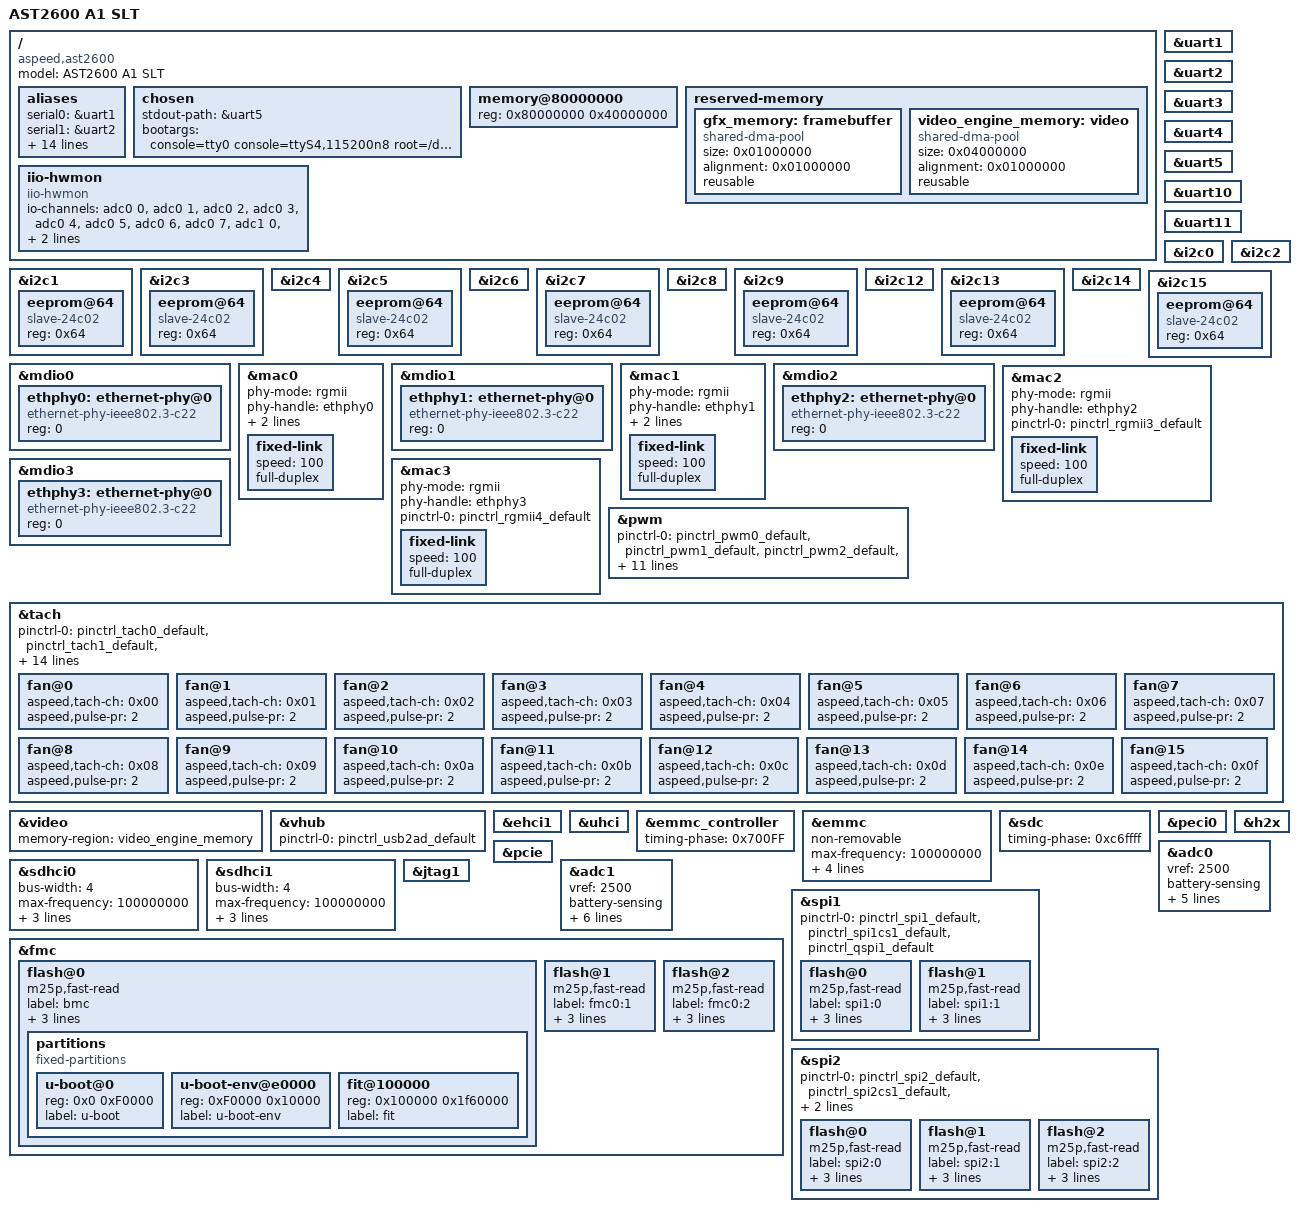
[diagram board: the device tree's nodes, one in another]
// SPDX-License-Identifier: GPL-2.0+
/dts-v1/;

#include "aspeed-g6.dtsi"

/ {
	model = "AST2600 A1 SLT";
	compatible = "aspeed,ast2600";

	aliases {
		serial0 = &uart1;
		serial1 = &uart2;
		serial2 = &uart3;
		serial3 = &uart4;
		serial4 = &uart5;
		serial5 = &uart6;
		serial6 = &uart7;
		serial7 = &uart8;
		serial8 = &uart9;
		serial9 = &uart10;
		serial10 = &uart11;
		serial11 = &uart12;
		serial12 = &uart13;
		mmc0 = &emmc;
		mmc1 = &sdhci0;
		mmc2 = &sdhci1;
	};

	chosen {
		stdout-path = &uart5;
		bootargs = "console=tty0 console=ttyS4,115200n8 root=/dev/ram rw init=/linuxrc";
	};

	memory@80000000 {
		device_type = "memory";
		reg = <0x80000000 0x40000000>;
	};

	reserved-memory {
		#address-cells = <1>;
		#size-cells = <1>;
		ranges;

		gfx_memory: framebuffer {
			size = <0x01000000>;
			alignment = <0x01000000>;
			compatible = "shared-dma-pool";
			reusable;
		};

		video_engine_memory: video {
			size = <0x04000000>;
			alignment = <0x01000000>;
			compatible = "shared-dma-pool";
			reusable;
		};
	};

	iio-hwmon {
		compatible = "iio-hwmon";
		io-channels = <&adc0 0>, <&adc0 1>, <&adc0 2>, <&adc0 3>,
				<&adc0 4>, <&adc0 5>, <&adc0 6>, <&adc0 7>,
				<&adc1 0>, <&adc1 1>, <&adc1 2>, <&adc1 3>,
				<&adc1 4>, <&adc1 5>, <&adc1 6>, <&adc1 7>;
	};	
};

&uart1 {
	status = "okay";
};

&uart2 {
	status = "okay";
};

&uart3 {
	status = "okay";
};

&uart4 {
	status = "okay";
};

&uart5 {
	status = "okay";
};

&uart10 {
	status = "okay";
};

&uart11 {
	status = "okay";
};

#if 0
&i3c0 {
	status = "okay";
};

&i3c1 {
	status = "okay";
};

&i3c2 {
        status = "okay";

        pinctrl-names = "default";
        pinctrl-0 = <&pinctrl_hvi3c3_default>;
};

&i3c3 {
        status = "okay";

        pinctrl-names = "default";
        pinctrl-0 = <&pinctrl_hvi3c4_default>;
};

&i3c4 {
	status = "okay";
};

&i3c5 {
	status = "okay";
};
#endif

&i2c0 {
	status = "okay";
};

&i2c1 {
	status = "okay";

	eeprom@64 {
		compatible = "slave-24c02";
		reg = <0x64>;
	};
};

&i2c2 {
	status = "okay";
};

&i2c3 {
	status = "okay";

	eeprom@64 {
		compatible = "slave-24c02";
		reg = <0x64>;
	};
};

&i2c4 {
	status = "okay";
};

&i2c5 {
	status = "okay";

	eeprom@64 {
		compatible = "slave-24c02";
		reg = <0x64>;
	};
};

&i2c6 {
	status = "okay";
};

&i2c7 {
	status = "okay";

	eeprom@64 {
		compatible = "slave-24c02";
		reg = <0x64>;
	};
};

&i2c8 {
	status = "okay";
};

&i2c9 {
	status = "okay";

	eeprom@64 {
		compatible = "slave-24c02";
		reg = <0x64>;
	};
};

&i2c12 {
	status = "okay";
};

&i2c13 {
	status = "okay";

	eeprom@64 {
		compatible = "slave-24c02";
		reg = <0x64>;
	};
};

&i2c14 {
	status = "okay";
};

&i2c15 {
	status = "okay";

	eeprom@64 {
		compatible = "slave-24c02";
		reg = <0x64>;
	};
};

&mdio0 {
	status = "okay";

	ethphy0: ethernet-phy@0 {
		compatible = "ethernet-phy-ieee802.3-c22";
		reg = <0>;
	};
};

&mac0 {
	status = "okay";

	phy-mode = "rgmii";
	phy-handle = <&ethphy0>;

	pinctrl-names = "default";
	pinctrl-0 = <&pinctrl_rgmii1_default>;
	no-hw-sg;

	fixed-link {
		speed = <100>;
		full-duplex;
	};
};

&mdio1 {
	status = "okay";

	ethphy1: ethernet-phy@0 {
		compatible = "ethernet-phy-ieee802.3-c22";
		reg = <0>;
	};
};

&mac1 {
	status = "okay";

	phy-mode = "rgmii";
	phy-handle = <&ethphy1>;

	pinctrl-names = "default";
	pinctrl-0 = <&pinctrl_rgmii2_default>;
	no-hw-sg;

	fixed-link {
		speed = <100>;
		full-duplex;
	};
};

&mdio2 {
	status = "okay";

	ethphy2: ethernet-phy@0 {
		compatible = "ethernet-phy-ieee802.3-c22";
		reg = <0>;
	};
};

&mac2 {
	status = "okay";

	phy-mode = "rgmii";
	phy-handle = <&ethphy2>;

	pinctrl-names = "default";
	pinctrl-0 = <&pinctrl_rgmii3_default>;

	fixed-link {
		speed = <100>;
		full-duplex;
	};
};

&mdio3 {
	status = "okay";

	ethphy3: ethernet-phy@0 {
		compatible = "ethernet-phy-ieee802.3-c22";
		reg = <0>;
	};
};

&mac3 {
	status = "okay";

	phy-mode = "rgmii";
	phy-handle = <&ethphy3>;

	pinctrl-names = "default";
	pinctrl-0 = <&pinctrl_rgmii4_default>;

	fixed-link {
		speed = <100>;
		full-duplex;
	};
};

&pwm {
	status = "okay";
	pinctrl-names = "default";
	pinctrl-0 = <&pinctrl_pwm0_default
			&pinctrl_pwm1_default
			&pinctrl_pwm2_default
			&pinctrl_pwm3_default
			&pinctrl_pwm4_default
			&pinctrl_pwm5_default
			&pinctrl_pwm6_default
			&pinctrl_pwm7_default
			&pinctrl_pwm8g1_default
			&pinctrl_pwm9g1_default
			&pinctrl_pwm10g1_default
			&pinctrl_pwm11g1_default
			&pinctrl_pwm12g1_default
			&pinctrl_pwm13g1_default
			&pinctrl_pwm14g1_default
			&pinctrl_pwm15g1_default>;
};

&tach {
	status = "okay";
	pinctrl-names = "default";
	pinctrl-0 = <&pinctrl_tach0_default
			&pinctrl_tach1_default
			&pinctrl_tach2_default
			&pinctrl_tach3_default
			&pinctrl_tach4_default
			&pinctrl_tach5_default
			&pinctrl_tach6_default
			&pinctrl_tach7_default
			&pinctrl_tach8_default
			&pinctrl_tach9_default
			&pinctrl_tach10_default
			&pinctrl_tach11_default
			&pinctrl_tach12_default
			&pinctrl_tach13_default
			&pinctrl_tach14_default
			&pinctrl_tach15_default>;
	fan@0 {
		aspeed,tach-ch = <0x00>;
		aspeed,pulse-pr = <2>;
	};

	fan@1 {
		aspeed,tach-ch = <0x01>;
		aspeed,pulse-pr = <2>;
	};

	fan@2 {
		aspeed,tach-ch = <0x02>;
		aspeed,pulse-pr = <2>;
	};

	fan@3 {
		aspeed,tach-ch = <0x03>;
		aspeed,pulse-pr = <2>;
	};

	fan@4 {
		aspeed,tach-ch = <0x04>;
		aspeed,pulse-pr = <2>;
	};

	fan@5 {
		aspeed,tach-ch = <0x05>;
		aspeed,pulse-pr = <2>;
	};

	fan@6 {
		aspeed,tach-ch = <0x06>;
		aspeed,pulse-pr = <2>;
	};

	fan@7 {
		aspeed,tach-ch = <0x07>;
		aspeed,pulse-pr = <2>;
	};

	fan@8 {
		aspeed,tach-ch = <0x08>;
		aspeed,pulse-pr = <2>;
	};

	fan@9 {
		aspeed,tach-ch = <0x09>;
		aspeed,pulse-pr = <2>;
	};

	fan@10 {
		aspeed,tach-ch = <0x0a>;
		aspeed,pulse-pr = <2>;
	};

	fan@11 {
		aspeed,tach-ch = <0x0b>;
		aspeed,pulse-pr = <2>;
	};

	fan@12 {
		aspeed,tach-ch = <0x0c>;
		aspeed,pulse-pr = <2>;
	};

	fan@13 {
		aspeed,tach-ch = <0x0d>;
		aspeed,pulse-pr = <2>;
	};

	fan@14 {
		aspeed,tach-ch = <0x0e>;
		aspeed,pulse-pr = <2>;
	};

	fan@15 {
		aspeed,tach-ch = <0x0f>;
		aspeed,pulse-pr = <2>;
	};
};

&video {
	status = "okay";
	memory-region = <&video_engine_memory>;
};

&vhub {
	status = "okay";
	pinctrl-names = "default";
#if 1
	pinctrl-0 = <&pinctrl_usb2ad_default>;
#else
	pinctrl-0 = <&pinctrl_usb2adp_default>;
#endif
};

#if 0
&ehci0 {
	status = "okay";
};
#endif

&ehci1 {
	status = "okay";
};

&uhci {
	status = "okay";
};

#if 0
&gfx {
	status = "okay";
	memory-region = <&gfx_memory>;
};
#endif

&emmc_controller {
	status = "okay";
	timing-phase = <0x700FF>;
};

&emmc {
	status = "okay";

	non-removable;
	max-frequency = <100000000>;
	sdhci-drive-type = /bits/ 8 <3>;
	bus-width = <8>;
	pinctrl-0 = <&pinctrl_emmc_default 
			&pinctrl_emmcg8_default>;
};

&sdc {
	status = "okay";
	timing-phase = <0xc6ffff>;
};

&sdhci0 {
	status = "okay";

	bus-width = <4>;
	max-frequency = <100000000>;
	sdhci-drive-type = /bits/ 8 <3>;
	/* SDR104/DDR50/SDR50 bits in CAPA2 is not supported */
	sdhci-caps-mask = <0x7 0x580000>;
	sdhci,wp-inverted;
};

&sdhci1 {
	status = "okay";

	bus-width = <4>;
	max-frequency = <100000000>;
	sdhci-drive-type = /bits/ 8 <3>;
	sdhci-caps-mask = <0x7 0x580000>;
	sdhci,wp-inverted;
};

&peci0 {
	status = "okay";
};

&pcie {
	status = "okay";
};

&h2x {
	status = "okay";
};

&adc0 {
	vref = <2500>;
	battery-sensing;
	status = "okay";

	pinctrl-0 = <&pinctrl_adc0_default &pinctrl_adc1_default
		&pinctrl_adc2_default &pinctrl_adc3_default
		&pinctrl_adc4_default &pinctrl_adc5_default
		&pinctrl_adc6_default &pinctrl_adc7_default>;
};

&adc1 {
	vref = <2500>;
	battery-sensing;
	status = "okay";

	pinctrl-0 = <&pinctrl_adc8_default &pinctrl_adc9_default
		&pinctrl_adc10_default &pinctrl_adc11_default
		&pinctrl_adc12_default &pinctrl_adc13_default
		&pinctrl_adc14_default &pinctrl_adc15_default>;
};

&jtag1 {
	status = "okay";
};

&fmc {
	status = "okay";

	flash@0 {
		status = "okay";
		m25p,fast-read;
		label = "bmc";
		spi-max-frequency = <50000000>;
		spi-tx-bus-width = <4>;
		spi-rx-bus-width = <4>;
		partitions {
			compatible = "fixed-partitions";
			#address-cells = <1>;
			#size-cells = <1>;

			u-boot@0 {
				reg = <0x0 0xF0000>;
				label = "u-boot";
			};

			u-boot-env@e0000 {
				reg = <0xF0000 0x10000>;
				label = "u-boot-env";
			};

			fit@100000 {
				reg = <0x100000 0x1f60000>;
				label = "fit";
			};

		};
	};

	flash@1 {
		status = "okay";
		m25p,fast-read;
		label = "fmc0:1";
		spi-max-frequency = <50000000>;
		spi-tx-bus-width = <4>;
		spi-rx-bus-width = <4>;
	};

	flash@2 {
		status = "okay";
		m25p,fast-read;
		label = "fmc0:2";
		spi-max-frequency = <50000000>;
		spi-tx-bus-width = <4>;
		spi-rx-bus-width = <4>;
	};
};

&spi1 {
	status = "okay";

	pinctrl-names = "default";
	pinctrl-0 = <&pinctrl_spi1_default &pinctrl_spi1cs1_default
				&pinctrl_qspi1_default>;

	flash@0 {
		status = "okay";
		m25p,fast-read;
		label = "spi1:0";
		spi-max-frequency = <50000000>;
		spi-tx-bus-width = <4>;
		spi-rx-bus-width = <4>;
	};

	flash@1 {
		status = "okay";
		m25p,fast-read;
		label = "spi1:1";
		spi-max-frequency = <50000000>;
		spi-tx-bus-width = <4>;
		spi-rx-bus-width = <4>;
	};
};

&spi2 {
	status = "okay";

	pinctrl-names = "default";
	pinctrl-0 = <&pinctrl_spi2_default &pinctrl_spi2cs1_default
				&pinctrl_spi2cs2_default &pinctrl_qspi2_default>;

	flash@0 {
		status = "okay";
		m25p,fast-read;
		label = "spi2:0";
		spi-max-frequency = <50000000>;
		spi-tx-bus-width = <4>;
		spi-rx-bus-width = <4>;
	};

	flash@1 {
		status = "okay";
		m25p,fast-read;
		label = "spi2:1";
		spi-max-frequency = <50000000>;
		spi-tx-bus-width = <4>;
		spi-rx-bus-width = <4>;
	};

	flash@2 {
		status = "okay";
		m25p,fast-read;
		label = "spi2:2";
		spi-max-frequency = <50000000>;
		spi-tx-bus-width = <4>;
		spi-rx-bus-width = <4>;
	};

};
